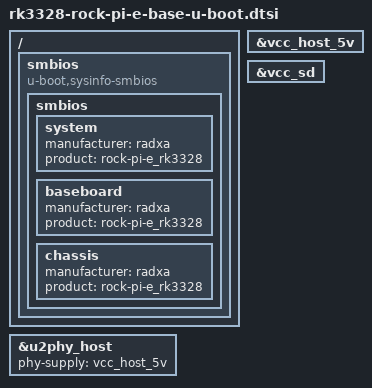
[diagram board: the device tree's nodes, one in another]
// SPDX-License-Identifier: GPL-2.0+
/*
 * (C) Copyright 2020 Radxa
 */

#include "rk3328-u-boot.dtsi"

/ {
	smbios {
		compatible = "u-boot,sysinfo-smbios";

		smbios {
			system {
				manufacturer = "radxa";
				product = "rock-pi-e_rk3328";
			};

			baseboard {
				manufacturer = "radxa";
				product = "rock-pi-e_rk3328";
			};

			chassis {
				manufacturer = "radxa";
				product = "rock-pi-e_rk3328";
			};
		};
	};
};

&u2phy_host {
	phy-supply = <&vcc_host_5v>;
};

&vcc_host_5v {
	/delete-property/ regulator-always-on;
	/delete-property/ regulator-boot-on;
};

&vcc_sd {
	bootph-pre-ram;
};
